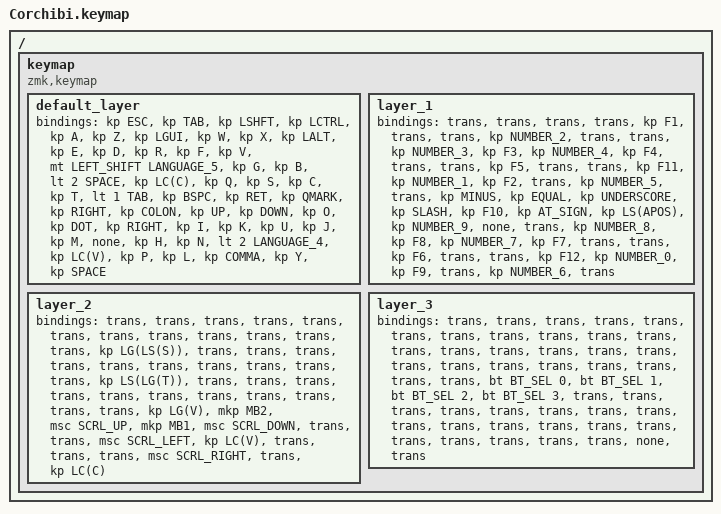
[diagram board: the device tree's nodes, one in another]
#include <dt-bindings/zmk/mouse.h>
#include <behaviors.dtsi>
#include <dt-bindings/zmk/bt.h>
#include <dt-bindings/zmk/keys.h>
#include <dt-bindings/zmk/pointing.h>

/ {
    keymap {
        compatible = "zmk,keymap";

        default_layer {
            bindings = <
&kp ESC  &kp TAB  &kp LSHFT  &kp LCTRL  &kp A  &kp Z  &kp LGUI  &kp W  &kp X  &kp LALT  &kp E  &kp D  &kp R  &kp F  &kp V  &mt LEFT_SHIFT LANGUAGE_5  &kp G  &kp B  &lt 2 SPACE  &kp LC(C)  &kp Q  &kp S  &kp C  &kp T  &lt 1 TAB  &kp BSPC  &kp RET  &kp QMARK  &kp RIGHT  &kp COLON  &kp UP  &kp DOWN  &kp O  &kp DOT  &kp RIGHT  &kp I  &kp K  &kp U  &kp J  &kp M  &none  &kp H  &kp N  &lt 2 LANGUAGE_4  &kp LC(V)  &kp P  &kp L  &kp COMMA  &kp Y  &kp SPACE
            >;
        };

        layer_1 {
            bindings = <
&trans  &trans  &trans  &trans  &kp F1  &trans  &trans  &kp NUMBER_2  &trans  &trans  &kp NUMBER_3  &kp F3  &kp NUMBER_4  &kp F4  &trans  &trans  &kp F5  &trans  &trans  &kp F11  &kp NUMBER_1  &kp F2  &trans  &kp NUMBER_5  &trans  &kp MINUS  &kp EQUAL  &kp UNDERSCORE  &kp SLASH  &kp F10  &kp AT_SIGN  &kp LS(APOS)  &kp NUMBER_9  &none  &trans  &kp NUMBER_8  &kp F8  &kp NUMBER_7  &kp F7  &trans  &trans  &kp F6  &trans  &trans  &kp F12  &kp NUMBER_0  &kp F9  &trans  &kp NUMBER_6  &trans
            >;
        };

        layer_2 {
            bindings = <
&trans  &trans  &trans  &trans  &trans  &trans  &trans  &trans  &trans  &trans  &trans  &trans  &kp LG(LS(S))  &trans  &trans  &trans  &trans  &trans  &trans  &trans  &trans  &trans  &trans  &kp LS(LG(T))  &trans  &trans  &trans  &trans  &trans  &trans  &trans  &trans  &trans  &trans  &trans  &kp LG(V)  &mkp MB2  &msc SCRL_UP  &mkp MB1  &msc SCRL_DOWN  &trans  &trans  &msc SCRL_LEFT  &kp LC(V)  &trans  &trans  &trans  &msc SCRL_RIGHT  &trans  &kp LC(C)
            >;
        };

        layer_3 {
            bindings = <
&trans  &trans  &trans  &trans  &trans  &trans  &trans  &trans  &trans  &trans  &trans  &trans  &trans  &trans  &trans  &trans  &trans  &trans  &trans  &trans  &trans  &trans  &trans  &trans  &trans  &bt BT_SEL 0  &bt BT_SEL 1  &bt BT_SEL 2  &bt BT_SEL 3  &trans  &trans  &trans  &trans  &trans  &trans  &trans  &trans  &trans  &trans  &trans  &trans  &trans  &trans  &trans  &trans  &trans  &trans  &trans  &none  &trans
            >;
        };
    };
};
